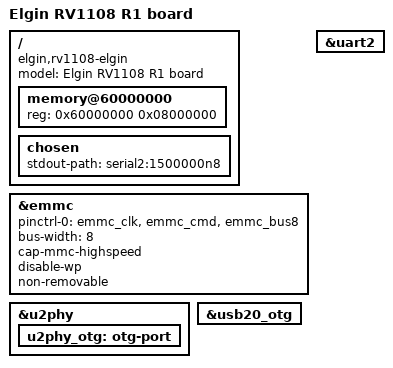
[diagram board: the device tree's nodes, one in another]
// SPDX-License-Identifier: GPL-2.0+
/*
 * (C) Copyright 2016 Rockchip Electronics Co., Ltd
 */

/dts-v1/;

#include "rv1108.dtsi"

/ {
	model = "Elgin RV1108 R1 board";
	compatible = "elgin,rv1108-elgin", "rockchip,rv1108";

	memory@60000000 {
		device_type = "memory";
		reg = <0x60000000 0x08000000>;
	};

	chosen {
		stdout-path = "serial2:1500000n8";
	};
};

&emmc {
	pinctrl-names = "default";
	pinctrl-0 = <&emmc_clk &emmc_cmd &emmc_bus8>;
	bus-width = <8>;
	cap-mmc-highspeed;
	disable-wp;
	non-removable;
	status = "okay";
};

&u2phy {
	status = "okay";

	u2phy_otg: otg-port {
		status = "okay";
	};
};

&uart2 {
	status = "okay";
};

&usb20_otg {
	status = "okay";
};
